VERSION ""

NS_ :

BS_:

BU_:

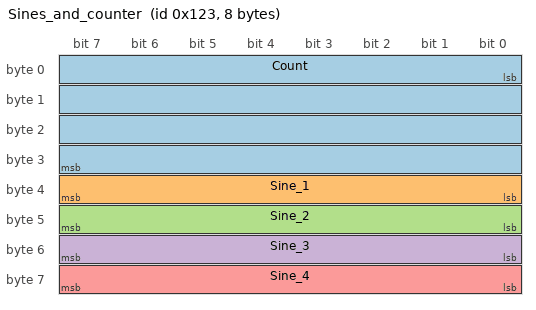
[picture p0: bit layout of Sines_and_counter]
BO_ 291 Sines_and_counter: 8 Vector__XXX
	SG_ Count : 0|32@1+ (1,0) [0|64431] "NA" Vector__XXX
	SG_ Sine_1 : 32|8@1+ (1,0) [0|256] "V" Vector__XXX
	SG_ Sine_2 : 40|8@1+ (1,0) [0|256] "A" Vector__XXX
	SG_ Sine_3 : 48|8@1+ (1,0) [0|256] "N" Vector__XXX
	SG_ Sine_4 : 56|8@1+ (1,0) [0|256] "kg" Vector__XXX

BA_DEF_ BO_  "VFrameFormat" ENUM  "StandardCAN","ExtendedCAN","reserved","J1939PG";
BA_DEF_  "DatabaseVersion" STRING ;
BA_DEF_  "BusType" STRING ;
BA_DEF_  "ProtocolType" STRING ;
BA_DEF_  "DatabaseCompiler" STRING ;
BA_DEF_DEF_  "VFrameFormat" "J1939PG";
BA_DEF_DEF_  "DatabaseVersion" "DEMO PLUS";
BA_DEF_DEF_  "BusType" "";
BA_DEF_DEF_  "ProtocolType" "";
BA_DEF_DEF_  "DatabaseCompiler" "";
BA_ "ProtocolType" "J1939";
BA_ "BusType" "CAN";
BA_ "DatabaseCompiler" "CSS ELECTRONICS (WWW.CSSELECTRONICS.COM)";
BA_ "DatabaseVersion" "1.0.0";
